# STM32G473 register map
File version: 2.2
CPU: CM4 r0p1, little endian, MPU, FPU, 4 interrupt priority bits
Registers are 32-bit, read-write, reset 0x0 unless marked. A register's access mark holds for its fields unless they carry their own. Offsets are from the block's base; [hi:lo] are bit positions; {n}, {i} and the like mark numbered series; 'fields as' and 'values as' point back to an identical list.

## SYSCFG — System configuration controller
Base 0x40010000
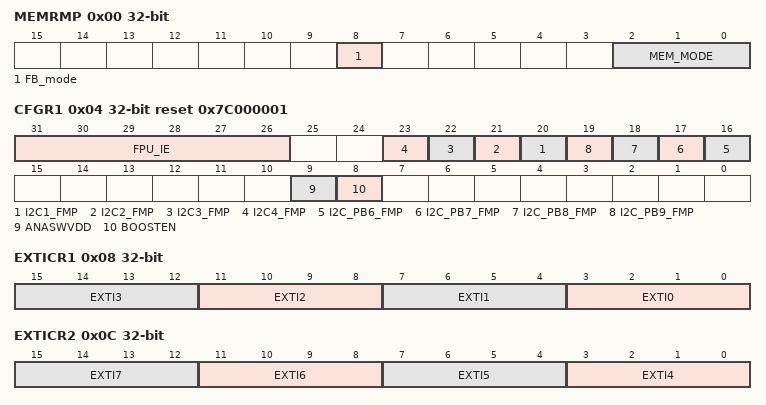
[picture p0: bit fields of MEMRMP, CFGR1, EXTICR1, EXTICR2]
0x00 MEMRMP — Remap Memory register
  [8] FB_mode — User Flash Bank mode
  [2:0] MEM_MODE — Memory mapping selection
0x04 CFGR1 reset 0x7C000001 — peripheral mode configuration register
  [31:26] FPU_IE — FPU Interrupts Enable
  [n+19] I2C{n}_FMP (n=1..4) — I2C1 FM+ drive capability enable
  [n+10] I2C_PB{n}_FMP (n=6..9) — FM+ drive capability on PB6
  [9] ANASWVDD — GPIO analog switch control voltage selection
  [8] BOOSTEN
0x08 EXTICR1 — external interrupt configuration register 1
  [4n+3:4n] EXTI{n} (n=0..3) — EXTI x configuration (x = 0 to 3)
0x0C EXTICR2 — external interrupt configuration register 2
  [4n-13:4n-16] EXTI{n} (n=4..7) — EXTI x configuration (x = 4 to 7)
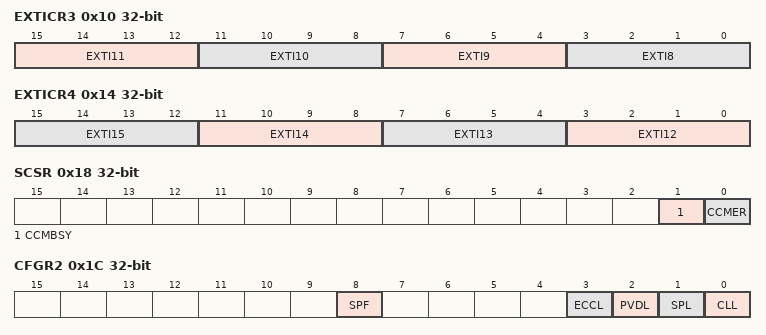
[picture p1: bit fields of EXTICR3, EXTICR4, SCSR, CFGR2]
0x10 EXTICR3 — external interrupt configuration register 3
  [15:12] EXTI11 — EXTI x configuration (x = 8 to 11)
  [11:8] EXTI10
  [7:4] EXTI9 — EXTI x configuration (x = 8 to 11)
  [3:0] EXTI8 — EXTI x configuration (x = 8 to 11)
0x14 EXTICR4 — external interrupt configuration register 4
  [4n-45:4n-48] EXTI{n} (n=12..15) — EXTI x configuration (x = 12 to 15)
0x18 SCSR access per field — CCM SRAM control and status register
  [1] CCMBSY ro — CCM SRAM busy by erase operation
  [0] CCMER rw — CCM SRAM Erase
0x1C CFGR2 — configuration register 2
  [8] SPF — SRAM Parity Flag
  [3] ECCL — ECC Lock
  [2] PVDL — PVD Lock
  [1] SPL — SRAM Parity Lock
  [0] CLL — Core Lockup Lock
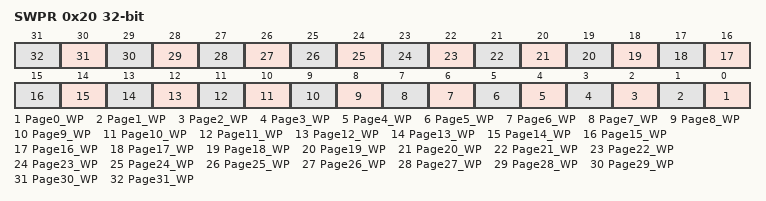
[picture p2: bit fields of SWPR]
0x20 SWPR — SRAM Write protection register 1
  [n] Page{n}_WP (n=0..31) — Write protection
0x24 SKR wo — SRAM2 Key Register
  [7:0] KEY — SRAM2 Key for software erase

## VREFBUF — Voltage reference buffer
Base 0x40010030
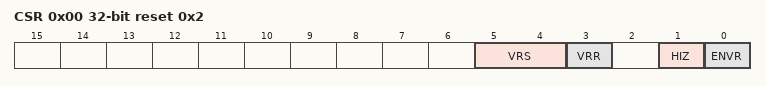
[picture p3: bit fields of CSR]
0x00 CSR access per field reset 0x2 — VREF_BUF Control and Status Register
  [5:4] VRS rw — Voltage reference scale
  [3] VRR ro — Voltage reference buffer ready
  [1] HIZ rw — High impedence mode for the VREF_BUF
  [0] ENVR rw — Enable Voltage Reference
0x04 CCR — VREF_BUF Calibration Control Register
  [5:0] TRIM — Trimming code

## COMP — Comparator control and status register
Base 0x40010200
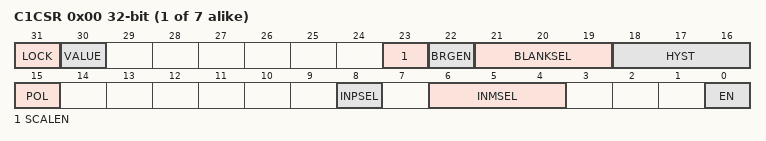
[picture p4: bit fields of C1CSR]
0x00 C{i}CSR (i=1..7; step 0x4) access per field — Comparator control/status register
  [31] LOCK rw, [30] VALUE ro, [23] SCALEN rw, [22] BRGEN rw, [21:19] BLANKSEL rw, [18:16] HYST rw, [15] POL rw, [8] INPSEL rw, [6:4] INMSEL rw, [0] EN rw

## ADC12_Common — Analog-to-Digital Converter
Base 0x50000300
Same registers: ADC345_Common 0x50000700
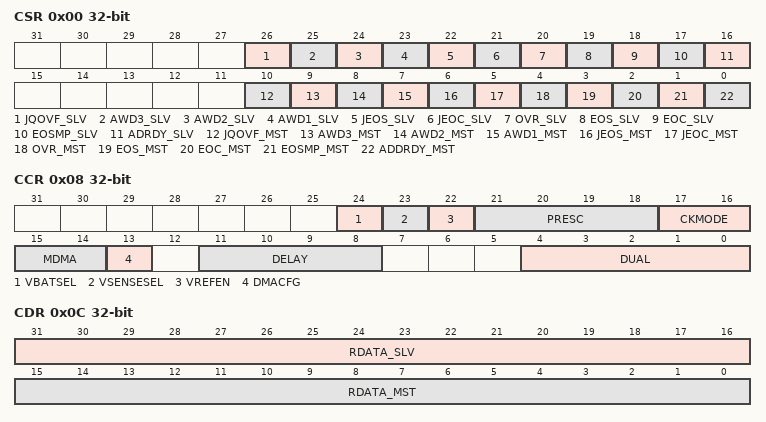
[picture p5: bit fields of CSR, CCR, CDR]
0x00 CSR ro — ADC Common status register
  [26] JQOVF_SLV — Injected Context Queue Overflow flag of the slave ADC
    0=NoOverflow (No injected context queue overflow has occurred); 1=Overflow (Injected context queue overflow has occurred)
  [25] AWD3_SLV — Analog watchdog 3 flag of the slave ADC
    0=NoEvent (No analog watchdog event occurred); 1=Event (Analog watchdog event occurred)
  [24] AWD2_SLV — Analog watchdog 2 flag of the slave ADC
    values as AWD3_SLV
  [23] AWD1_SLV — Analog watchdog 1 flag of the slave ADC
    values as AWD3_SLV
  [22] JEOS_SLV — End of injected sequence flag of the slave ADC
    0=NotComplete (Injected sequence is not complete); 1=Complete (Injected sequence complete)
  [21] JEOC_SLV — End of injected conversion flag of the slave ADC
    0=NotComplete (Injected conversion is not complete); 1=Complete (Injected conversion complete)
  [20] OVR_SLV — Overrun flag of the slave ADC
    0=No overrun occurred; 1=Overrun occurred
  [19] EOS_SLV — End of regular sequence flag of the slave ADC
    0=NotComplete (Regular sequence is not complete); 1=Complete (Regular sequence complete)
  [18] EOC_SLV — End of regular conversion of the slave ADC
    0=NotComplete (Regular conversion is not complete); 1=Complete (Regular conversion complete)
  [17] EOSMP_SLV
    0=NotEnded (End of sampling phase no yet reached); 1=Ended (End of sampling phase reached)
  [16] ADRDY_SLV
    0=NotReady (ADC is not ready to start conversion); 1=Ready (ADC is ready to start conversion)
  [10] JQOVF_MST
    values as JQOVF_SLV
  [9] AWD3_MST
    values as AWD3_SLV
  [8] AWD2_MST
    values as AWD3_SLV
  [7] AWD1_MST
    values as AWD3_SLV
  [6] JEOS_MST
    values as JEOS_SLV
  [5] JEOC_MST
    values as JEOC_SLV
  [4] OVR_MST
    0=No overrun occurred; 1=Overrun occurred
  [3] EOS_MST
    values as EOS_SLV
  [2] EOC_MST
    values as EOC_SLV
  [1] EOSMP_MST
    values as EOSMP_SLV
  [0] ADDRDY_MST
0x08 CCR — ADC common control register
  [24] VBATSEL — VBAT selection
    0=Disabled (V_BAT channel disabled); 1=Enabled (V_BAT channel enabled)
  [23] VSENSESEL — VTS selection
    0=Disabled (Temperature sensor channel disabled); 1=Enabled (Temperature sensor channel enabled)
  [22] VREFEN — VREFINT enable
    0=Disabled (V_REFINT channel disabled); 1=Enabled (V_REFINT channel enabled)
  [21:18] PRESC — ADC prescaler
  [17:16] CKMODE — ADC clock mode
    0=Asynchronous (Use Kernel Clock adc_ker_ck_input divided by PRESC. Asynchronous to AHB clock); 1=SyncDiv1 (Use AHB clock rcc_hclk3. In this case rcc_hclk must equal sys_d1cpre_ck); 2=SyncDiv2 (Use AHB clock rcc_hclk3 divided by 2); 3=SyncDiv4 (Use AHB clock rcc_hclk3 divided by 4)
  [15:14] MDMA — Direct memory access mode for multi ADC mode
  [13] DMACFG — DMA configuration (for multi-ADC mode)
  [11:8] DELAY — Delay between 2 sampling phases
  [4:0] DUAL — Dual ADC mode selection
    0=Independent mode; 1=DualRJ (Dual, combined regular simultaneous + injected simultaneous mode); 2=DualRA (Dual, combined regular simultaneous + alternate trigger mode); 3=DualIJ (Dual, combined interleaved mode + injected simultaneous mode); 5=DualJ (Dual, injected simultaneous mode only); 6=Dual, regular simultaneous mode only; 7=Dual, interleaved mode only; 9=Dual, alternate trigger mode only
0x0C CDR ro — ADC common regular data register for dual and triple modes
  [31:16] RDATA_SLV — Regular data of the slave ADC
  [15:0] RDATA_MST — Regular data of the master ADC
